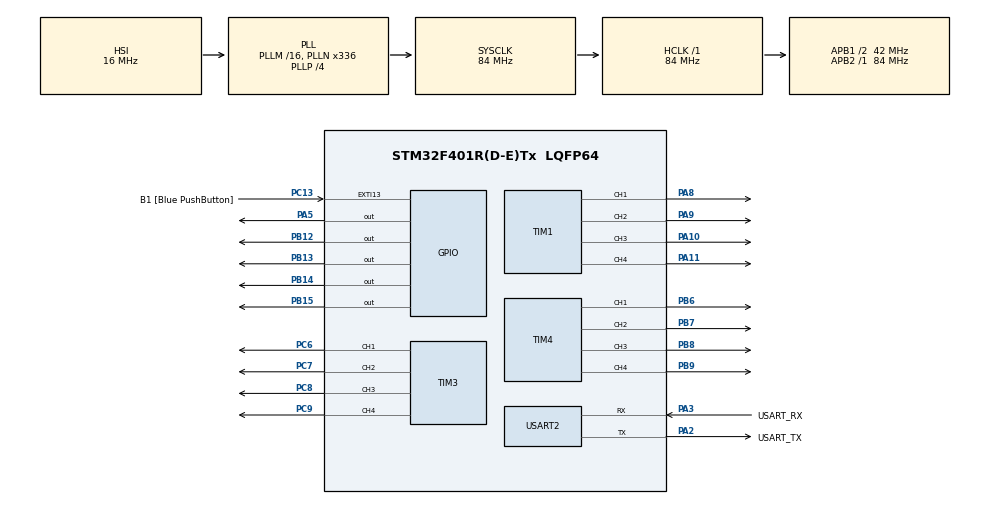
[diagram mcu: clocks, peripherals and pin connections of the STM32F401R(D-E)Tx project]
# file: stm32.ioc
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Mcu.Family=STM32F4
Mcu.Name=STM32F401R(D-E)Tx
Mcu.Package=LQFP64
NVIC.PriorityGroup=NVIC_PRIORITYGROUP_4
PA10.Signal=S_TIM1_CH3
PA11.Signal=S_TIM1_CH4
PA13.GPIO_Label=TMS
PA13.Mode=Trace_Asynchronous_SW
PA13.Signal=SYS_JTMS-SWDIO
PA14.GPIO_Label=TCK
PA14.Mode=Trace_Asynchronous_SW
PA14.Signal=SYS_JTCK-SWCLK
PA2.GPIO_Label=USART_TX
PA2.GPIO_Mode=GPIO_MODE_AF_PP
PA2.GPIO_PuPd=GPIO_NOPULL
PA2.GPIO_Speed=GPIO_SPEED_FREQ_LOW
PA2.Mode=Asynchronous
PA2.Signal=USART2_TX
PA3.GPIO_Label=USART_RX
PA3.GPIO_Mode=GPIO_MODE_AF_PP
PA3.GPIO_PuPd=GPIO_NOPULL
PA3.GPIO_Speed=GPIO_SPEED_FREQ_LOW
PA3.Mode=Asynchronous
PA3.Signal=USART2_RX
PA5.Signal=GPIO_Output
PA8.Signal=S_TIM1_CH1
PA9.Signal=S_TIM1_CH2
PB12.Signal=GPIO_Output
PB13.Signal=GPIO_Output
PB14.Signal=GPIO_Output
PB15.Signal=GPIO_Output
PB3.GPIO_Label=SWO
PB3.Mode=Trace_Asynchronous_SW
PB3.Signal=SYS_JTDO-SWO
PB6.Signal=S_TIM4_CH1
PB7.Signal=S_TIM4_CH2
PB8.Signal=S_TIM4_CH3
PB9.Signal=S_TIM4_CH4
PC13-ANTI_TAMP.GPIO_Label=B1 [Blue PushButton]
PC13-ANTI_TAMP.GPIO_ModeDefaultEXTI=GPIO_MODE_IT_FALLING
PC13-ANTI_TAMP.GPIO_PuPd=GPIO_NOPULL
PC13-ANTI_TAMP.Signal=GPXTI13
PC14-OSC32_IN.Mode=LSE-External-Oscillator
PC14-OSC32_IN.Signal=RCC_OSC32_IN
PC15-OSC32_OUT.Mode=LSE-External-Oscillator
PC15-OSC32_OUT.Signal=RCC_OSC32_OUT
PC6.Signal=S_TIM3_CH1
PC7.Signal=S_TIM3_CH2
PC8.Signal=S_TIM3_CH3
PC9.Signal=S_TIM3_CH4
PH0\ -\ OSC_IN.Mode=HSE-External-Clock-Source
PH0\ -\ OSC_IN.Signal=RCC_OSC_IN
PH1\ -\ OSC_OUT.Mode=HSE-External-Clock-Source
PH1\ -\ OSC_OUT.Signal=RCC_OSC_OUT
ProjectManager.HeapSize=0x200
ProjectManager.StackSize=0x400
ProjectManager.TargetToolchain=Makefile
RCC.48MHZClocksFreq_Value=48000000
RCC.AHBFreq_Value=84000000
RCC.APB1CLKDivider=RCC_HCLK_DIV2
RCC.APB1Freq_Value=42000000
RCC.APB1TimFreq_Value=84000000
RCC.APB2Freq_Value=84000000
RCC.APB2TimFreq_Value=84000000
RCC.CortexFreq_Value=84000000
RCC.HCLKFreq_Value=84000000
RCC.HSE_VALUE=8000000
RCC.HSI_VALUE=16000000
RCC.PLLN=336
RCC.PLLP=RCC_PLLP_DIV4
RCC.PLLQ=7
RCC.SYSCLKFreq_VALUE=84000000
RCC.SYSCLKSource=RCC_SYSCLKSOURCE_PLLCLK
RCC.VCOOutputFreq_Value=336000000
SH.S_TIM1_CH1.0=TIM1_CH1,PWM Generation1 CH1
SH.S_TIM1_CH2.0=TIM1_CH2,PWM Generation2 CH2
SH.S_TIM1_CH3.0=TIM1_CH3,PWM Generation3 CH3
SH.S_TIM1_CH4.0=TIM1_CH4,PWM Generation4 CH4
SH.S_TIM3_CH1.0=TIM3_CH1,PWM Generation1 CH1
SH.S_TIM3_CH2.0=TIM3_CH2,PWM Generation2 CH2
SH.S_TIM3_CH3.0=TIM3_CH3,PWM Generation3 CH3
SH.S_TIM3_CH4.0=TIM3_CH4,PWM Generation4 CH4
SH.S_TIM4_CH1.0=TIM4_CH1,PWM Generation1 CH1
SH.S_TIM4_CH2.0=TIM4_CH2,PWM Generation2 CH2
SH.S_TIM4_CH3.0=TIM4_CH3,PWM Generation3 CH3
SH.S_TIM4_CH4.0=TIM4_CH4,PWM Generation4 CH4
TIM1.Channel-PWM\ Generation1\ CH1=TIM_CHANNEL_1
TIM1.Channel-PWM\ Generation2\ CH2=TIM_CHANNEL_2
TIM1.Channel-PWM\ Generation3\ CH3=TIM_CHANNEL_3
TIM1.Channel-PWM\ Generation4\ CH4=TIM_CHANNEL_4
TIM3.Channel-PWM\ Generation1\ CH1=TIM_CHANNEL_1
TIM3.Channel-PWM\ Generation2\ CH2=TIM_CHANNEL_2
TIM3.Channel-PWM\ Generation3\ CH3=TIM_CHANNEL_3
TIM3.Channel-PWM\ Generation4\ CH4=TIM_CHANNEL_4
TIM4.Channel-PWM\ Generation1\ CH1=TIM_CHANNEL_1
TIM4.Channel-PWM\ Generation2\ CH2=TIM_CHANNEL_2
TIM4.Channel-PWM\ Generation3\ CH3=TIM_CHANNEL_3
TIM4.Channel-PWM\ Generation4\ CH4=TIM_CHANNEL_4
USART2.VirtualMode=VM_ASYNC
board=NUCLEO-F401RE

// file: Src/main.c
/* USER CODE BEGIN Header */
/**
  ******************************************************************************
  * @file           : main.c
  * @brief          : Main program body
  ******************************************************************************
  * @attention
  *
  * Copyright (c) 2026 STMicroelectronics.
  * All rights reserved.
  *
  * This software is licensed under terms that can be found in the LICENSE file
  * in the root directory of this software component.
  * If no LICENSE file comes with this software, it is provided AS-IS.
  *
  ******************************************************************************
  */
/* USER CODE END Header */
#include "main.h"
#include "tim.h"
#include "usart.h"
#include "gpio.h"

void SystemClock_Config(void);
/* USER CODE BEGIN PFP */
extern void app_main(void);  /* implemented in app.cpp, runs the JLed loop */
/* USER CODE END PFP */

int main(void)
{

  /* MCU Configuration--------------------------------------------------------*/

  /* Reset of all peripherals, Initializes the Flash interface and the Systick. */
  HAL_Init();

  /* Configure the system clock */
  SystemClock_Config();

  /* Initialize all configured peripherals */
  MX_GPIO_Init();
  MX_USART2_UART_Init();
  MX_TIM1_Init();
  MX_TIM3_Init();
  MX_TIM4_Init();
  /* USER CODE BEGIN 2 */
  /* Hand control to the C++ side. app_main() creates the JLed objects (after
     the MX_TIMx_Init() calls above, as the Stm32CubeHal ctor starts PWM and
     reads htim->Init.Period eagerly) and runs the update loop; it never returns. */
  app_main();
  /* USER CODE END 2 */

  /* Infinite loop */
  while (1)
  {

  }
}

void SystemClock_Config(void)
{
  RCC_OscInitTypeDef RCC_OscInitStruct = {0};
  RCC_ClkInitTypeDef RCC_ClkInitStruct = {0};

  /** Configure the main internal regulator output voltage
  */
  __HAL_RCC_PWR_CLK_ENABLE();
  __HAL_PWR_VOLTAGESCALING_CONFIG(PWR_REGULATOR_VOLTAGE_SCALE2);

  /** Initializes the RCC Oscillators according to the specified parameters
  * in the RCC_OscInitTypeDef structure.
  */
  RCC_OscInitStruct.OscillatorType = RCC_OSCILLATORTYPE_HSI;
  RCC_OscInitStruct.HSIState = RCC_HSI_ON;
  RCC_OscInitStruct.HSICalibrationValue = RCC_HSICALIBRATION_DEFAULT;
  RCC_OscInitStruct.PLL.PLLState = RCC_PLL_ON;
  RCC_OscInitStruct.PLL.PLLSource = RCC_PLLSOURCE_HSI;
  RCC_OscInitStruct.PLL.PLLM = 16;
  RCC_OscInitStruct.PLL.PLLN = 336;
  RCC_OscInitStruct.PLL.PLLP = RCC_PLLP_DIV4;
  RCC_OscInitStruct.PLL.PLLQ = 7;
  if (HAL_RCC_OscConfig(&RCC_OscInitStruct) != HAL_OK)
  {
    Error_Handler();
  }

  /** Initializes the CPU, AHB and APB buses clocks
  */
  RCC_ClkInitStruct.ClockType = RCC_CLOCKTYPE_HCLK|RCC_CLOCKTYPE_SYSCLK
                              |RCC_CLOCKTYPE_PCLK1|RCC_CLOCKTYPE_PCLK2;
  RCC_ClkInitStruct.SYSCLKSource = RCC_SYSCLKSOURCE_PLLCLK;
  RCC_ClkInitStruct.AHBCLKDivider = RCC_SYSCLK_DIV1;
  RCC_ClkInitStruct.APB1CLKDivider = RCC_HCLK_DIV2;
  RCC_ClkInitStruct.APB2CLKDivider = RCC_HCLK_DIV1;

  if (HAL_RCC_ClockConfig(&RCC_ClkInitStruct, FLASH_LATENCY_2) != HAL_OK)
  {
    Error_Handler();
  }
}

void Error_Handler(void)
{
  __disable_irq();
  while (1)
  {
  }
}
